# GD32E11x register map
File version: 1.0
GD32E11x ARM 32-bit Cortex-M4 Microcontroller based device
CPU: CM4 r2p1, little endian, no MPU, FPU, 4 interrupt priority bits
Registers are 32-bit, read-write, reset 0x0 unless marked. A register's access mark holds for its fields unless they carry their own. Offsets are from the block's base; lines under a group give offsets from that group; [hi:lo] are bit positions; {n}, {i} and the like mark numbered series; 'fields as' and 'values as' point back to an identical list; <NAME> marks a mode.

## Memory map
0x40000000 TIMER1 size 0x400 — General-purpose-timers
0x40000400 TIMER2 size 0x400
0x40000800 TIMER3 size 0x400
0x40000C00 TIMER4 size 0x400
0x40001000 TIMER5 size 0x400 — Basic-timers
0x40001400 TIMER6 size 0x400
0x40001800 TIMER11 size 0x400
0x40001C00 TIMER12 size 0x400
0x40002000 TIMER13 size 0x400
0x40002800 RTC size 0x400 — Real-time clock
0x40002C00 WWDGT size 0x400 — Window watchdog timer
0x40003000 FWDGT size 0x400 — free watchdog timer
0x40003800 SPI1 size 0x400
0x40003C00 SPI2 size 0x400
0x40004400 USART1 size 0x400
0x40004800 USART2 size 0x400
0x40004C00 UART3 size 0x400 — Universal asynchronous receiver transmitter
0x40005000 UART4 size 0x400
0x40005400 I2C0 size 0x400 — Inter integrated circuit
0x40005800 I2C1 size 0x400
0x40006C00 BKP size 0x400 — Backup registers
0x40007000 PMU size 0x400 — Power management unit
0x40007400 DAC size 0x400 — Digital-to-analog converter
0x4000C800 CTC size 0x400 — Clock trim controller
0x40010000 AFIO size 0x400 — Alternate-function I/Os
0x40010400 EXTI size 0x400 — External interrupt/event controller
0x40010800 GPIOA size 0x400 — General-purpose I/Os
0x40010C00 GPIOB size 0x400
0x40011000 GPIOC size 0x400
0x40011400 GPIOD size 0x400
0x40011800 GPIOE size 0x400
0x40012400 ADC0 size 0x400 — Analog to digital converter
0x40012800 ADC1 size 0x400 — Analog to digital converter
0x40012C00 TIMER0 size 0x400 — Advanced-timers
0x40013000 SPI0 size 0x400 — Serial peripheral interface
0x40013400 TIMER7 size 0x400
0x40013800 USART0 size 0x400 — Universal synchronous asynchronous receiver transmitter
0x40014C00 TIMER8 size 0x400 — General-purpose-timers
0x40015000 TIMER9 size 0x400 — General-purpose-timers
0x40015400 TIMER10 size 0x400
0x40020000 DMA0 size 0x400 — DMA controller
0x40020400 DMA1 size 0x400
0x40021000 RCU size 0x400 — Reset and clock unit
0x40022000 FMC size 0x400
0x40023000 CRC size 0x400 — cyclic redundancy check calculation unit
0x50000000 USBFS_GLOBAL size 0x400 — USB full speed global registers
0x50000400 USBFS_HOST size 0x400 — USB on the go full speed host
0x50000800 USBFS_DEVICE size 0x400 — USB on the go full speed device
0x50000E00 USBFS_PWRCLK size 0x100 — USB on the go full speed
0xA0000000 EXMC size 0x400 — External memory controller
0xE000E100 NVIC size 0xF00 — Nested Vectored Interrupt Controller
0xE0042000 DBG size 0x400 — Debug support

## Interrupts
0 WWDGT
2 Tamper (BKP)
3 RTC
4 FMC
5 RCU_CTC (CTC, RCU)
6 EXTI_Line0 (EXTI)
7 EXTI_Line1 (EXTI)
8 EXTI_Line2 (EXTI)
9 EXTI_Line3 (EXTI)
10 EXTI_Line4 (EXTI)
11 DMA0_Channel0 (DMA0)
12 DMA0_Channel1 (DMA0)
13 DMA0_Channel2 (DMA0)
14 DMA0_Channel3 (DMA0)
15 DMA0_Channel4 (DMA0)
16 DMA0_Channel5 (DMA0)
17 DMA0_Channel6 (DMA0)
18 ADC0_1 (ADC0, ADC1)
23 EXTI_line9_5 (EXTI)
24 TIMER0_BRK_TIMER8 (TIMER0, TIMER8)
25 TIMER0_UP_TIMER9 (TIMER0, TIMER9)
26 TIMER0_TRG_CMT_TIMER10 (TIMER0, TIMER10)
27 TIMER0_Channel (TIMER0)
28 TIMER1
29 TIMER2
30 TIMER3
31 I2C0_EV (I2C0)
32 I2C0_ER (I2C0)
33 I2C1_EV (I2C1)
34 I2C1_ER (I2C1)
35 SPI0
36 SPI1
37 USART0
38 USART1
39 USART2
40 EXTI_line15_10 (EXTI)
41 RTC_Alarm (RTC)
42 USBFS_WKUP (USBFS_GLOBAL)
43 TIMER7_BRK_TIMER11 (TIMER7, TIMER11)
44 TIMER7_UP_TIMER12 (TIMER7, TIMER12)
45 TIMER7_TRG_CMT_TIMER13 (TIMER7, TIMER13)
46 TIMER7_Channel (TIMER7)
48 EXMC
50 TIMER4
51 SPI2
52 UART3
53 UART4
54 TIMER5
55 TIMER6
56 DMA1_Channel0 (DMA1)
57 DMA1_Channel1 (DMA1)
58 DMA1_Channel2 (DMA1)
59 DMA1_Channel3_4 (DMA1)
67 USBFS (USBFS_GLOBAL)

## AFIO — Alternate-function I/Os
Base 0x40010000
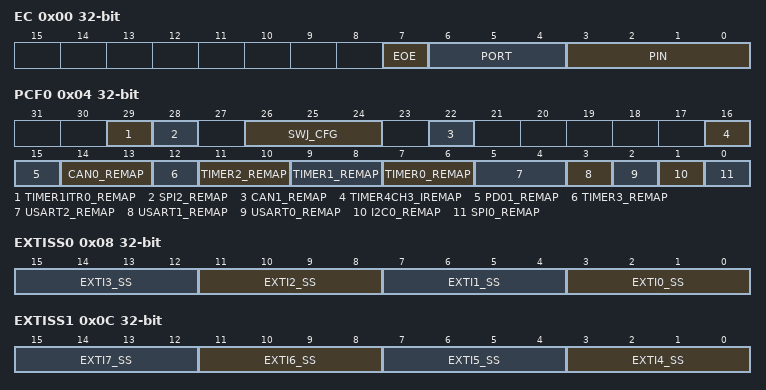
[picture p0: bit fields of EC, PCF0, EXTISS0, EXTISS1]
0x00 EC — Event control register
  [7] EOE — Event output enable
  [6:4] PORT — Event output port selection
  [3:0] PIN — Event output pin selection
0x04 PCF0 — AFIO port configuration register 0
  [29] TIMER1ITR0_REMAP — TIMER1 internal trigger 0 remapping
  [28] SPI2_REMAP — SPI2/I2S2 remapping
  [26:24] SWJ_CFG — Serial wire JTAG configuration
  [22] CAN1_REMAP — CAN1 I/O remapping
  [16] TIMER4CH3_IREMAP — TIMER4 channel3 internal remapping
  [15] PD01_REMAP — Port D0/Port D1 mapping on OSC_IN/OSC_OUT
  [14:13] CAN0_REMAP — CAN0 alternate interface remapping
  [12] TIMER3_REMAP — TIMER3 remapping
  [11:10] TIMER2_REMAP — TIMER2 remapping
  [9:8] TIMER1_REMAP — TIMER1 remapping
  [7:6] TIMER0_REMAP — TIMER0 remapping
  [5:4] USART2_REMAP — USART2 remapping
  [3] USART1_REMAP — USART1 remapping
  [2] USART0_REMAP — USART0 remapping
  [1] I2C0_REMAP — I2C0 remapping
  [0] SPI0_REMAP — SPI0 remapping
0x08 EXTISS0 — EXTI sources selection register 0
  [4n+3:4n] EXTI{n}_SS (n=0..3) — EXTI {n} sources selection
0x0C EXTISS1 — EXTI sources selection register 1
  [4n-13:4n-16] EXTI{n}_SS (n=4..7) — EXTI {n} sources selection
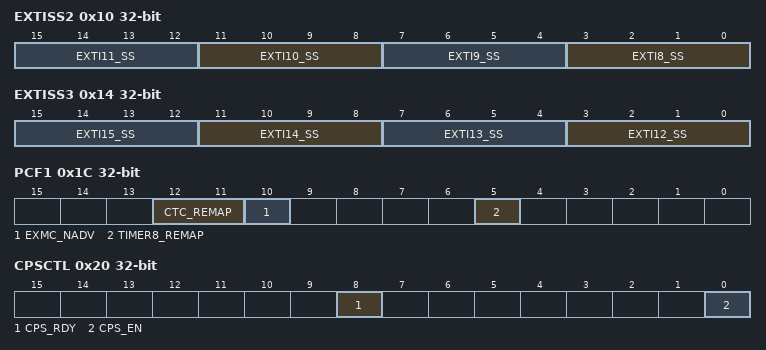
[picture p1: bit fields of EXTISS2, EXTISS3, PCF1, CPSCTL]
0x10 EXTISS2 — EXTI sources selection register 2
  [4n-29:4n-32] EXTI{n}_SS (n=8..11) — EXTI {n} sources selection
0x14 EXTISS3 — EXTI sources selection register 3
  [4n-45:4n-48] EXTI{n}_SS (n=12..15) — EXTI {n} sources selection
0x1C PCF1 — AFIO port configuration register 1
  [12:11] CTC_REMAP — CTC remapping
  [10] EXMC_NADV — EXMC_NADV connect/disconnect
  [5] TIMER8_REMAP — TIMER8 remapping
0x20 CPSCTL — IO compensation control register
  [8] CPS_RDY — I/O compensation cell is really or not
  [0] CPS_EN — I/O compensation cell enable
